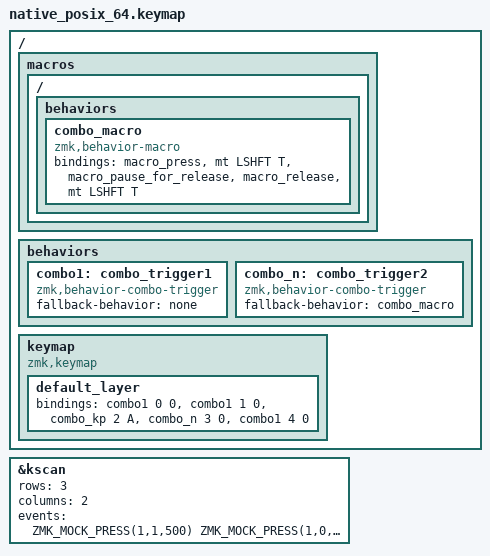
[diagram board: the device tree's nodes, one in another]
#include <dt-bindings/zmk/keys.h>
#include <behaviors.dtsi>
#include <dt-bindings/zmk/kscan_mock.h>


#define ZMK_COMBO(name, combo_bindings, keypos, combo_term) \
/ { \
    combos { \
        compatible = "zmk,combos"; \
        combo_ ## name { \
            triggers = <keypos>; \
            bindings = <combo_bindings>; \
            timeout-ms = <combo_term>; \
        }; \
    }; \
};

ZMK_COMBO(qmark, &kp QMARK,     0 3, 30)
ZMK_COMBO(dllr,  &kp DLLR,      1 3, 50)
ZMK_COMBO(tilde, &kp TILDE,     3 4, 50)

/ {

    macros {
        ZMK_MACRO(combo_macro, bindings
                = <&macro_press &mt LSHFT T>
                , <&macro_pause_for_release>
                , <&macro_release &mt LSHFT T>;
                )
    };

    behaviors {
        combo1: combo_trigger1{
            compatible = "zmk,behavior-combo-trigger";
            #binding-cells = <2>;
            fallback-behavior = <&none>;
        };
        combo_n: combo_trigger2{
            compatible = "zmk,behavior-combo-trigger";
            #binding-cells = <2>;
            fallback-behavior = <&combo_macro>;
        };
    };

    keymap {
        compatible = "zmk,keymap";

        default_layer {
            bindings = <
            &combo1 0 0 &combo1 1 0 &combo_kp 2 A &combo_n 3 0 &combo1 4 0
            >;
        };
    };
};

&kscan {
    rows = <3>;
    columns = <2>;
    events = <
    ZMK_MOCK_PRESS(1,1,500)
    ZMK_MOCK_PRESS(1,0,100)
    ZMK_MOCK_RELEASE(1,0,500)
    ZMK_MOCK_RELEASE(1,1,0)
    >;
};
